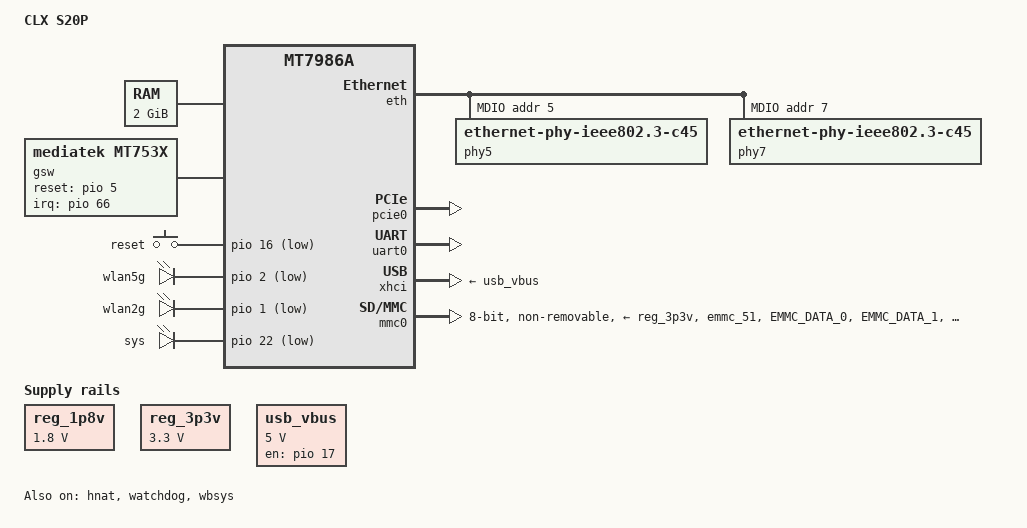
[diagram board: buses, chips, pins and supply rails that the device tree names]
// SPDX-License-Identifier: GPL-2.0-or-later OR MIT

/dts-v1/;
#include "mt7986a.dtsi"
#include "mt7986a-pinctrl.dtsi"
#include <dt-bindings/input/input.h>
#include <dt-bindings/gpio/gpio.h>
#include <dt-bindings/leds/common.h>

/ {
	model = "CLX S20P";
	compatible = "clx,s20p-gsw", "mediatek,mt7986a-emmc-rfb";

	aliases {
		led-boot = &led_sys;
		led-failsafe = &led_sys;
		led-running = &led_sys;
		led-upgrade = &led_sys;
	};

	chosen {
		bootargs = "console=ttyS0,115200n1 loglevel=8 \
			    earlycon=uart8250,mmio32,0x11002000 \
			    root=PARTLABEL=rootfs rootwait rootfstype=squashfs,f2fs";
	};

	memory {
		reg = <0 0x40000000 0 0x80000000>;
	};

	gsw: gsw@0 {
		compatible = "mediatek,mt753x";
		mediatek,ethsys = <&ethsys>;
		#address-cells = <1>;
		#size-cells = <0>;
	};

	gpio-keys {
		compatible = "gpio-keys";

		button-reset {
			label = "reset";
			linux,code = <KEY_RESTART>;
			gpios = <&pio 16 GPIO_ACTIVE_LOW>;
		};
	};

	gpio-leds {
		compatible = "gpio-leds";

		led_wlan5g: led_wlan5g {
			label = "wlan5g";
			gpios = <&pio 2 GPIO_ACTIVE_LOW>;
		};

		led_wlan2g: led_wlan2g {
			label = "wlan2g";
			gpios = <&pio 1 GPIO_ACTIVE_LOW>;
		};

		led_sys: led_sys {
			label = "sys";
			gpios = <&pio 22 GPIO_ACTIVE_LOW>;
		};
	};

	reg_1p8v: regulator-1p8v {
		compatible = "regulator-fixed";
		regulator-name = "fixed-1.8V";
		regulator-min-microvolt = <1800000>;
		regulator-max-microvolt = <1800000>;
		regulator-boot-on;
		regulator-always-on;
	};

	reg_3p3v: regulator-3p3v {
		compatible = "regulator-fixed";
		regulator-name = "fixed-3.3V";
		regulator-min-microvolt = <3300000>;
		regulator-max-microvolt = <3300000>;
		regulator-boot-on;
		regulator-always-on;
	};

	usb_vbus: regulator-usb-vbus {
		compatible = "regulator-fixed";
		regulator-name = "usb_vbus";
		regulator-min-microvolt = <5000000>;
		regulator-max-microvolt = <5000000>;
		gpios = <&pio 17 GPIO_ACTIVE_HIGH>;
		enable-active-high;
		regulator-boot-on;
	};
};

&eth {
	status = "okay";

	gmac0: mac@0 {
		compatible = "mediatek,eth-mac";
		reg = <0>;
		phy-mode = "2500base-x";
		ext-phy-reg = <5>;
		ext-phy-reset-gpios = <&pio 48 GPIO_ACTIVE_HIGH>;
		fixed-link {
			speed = <2500>;
			full-duplex;
			pause;
		};
	};

	gmac1: mac@1 {
		compatible = "mediatek,eth-mac";
		reg = <1>;
		phy-mode = "2500base-x";
		ext-phy-reg = <7>;
		ext-phy-reset-gpios = <&pio 6 GPIO_ACTIVE_HIGH>;
		fixed-link {
			speed = <2500>;
			full-duplex;
			pause;
		};
	};

	mdio: mdio-bus {
		#address-cells = <1>;
		#size-cells = <0>;

		phy5: phy@5 {
			compatible = "ethernet-phy-ieee802.3-c45";
			reg = <5>;
		};

		phy7: phy@7 {
			compatible = "ethernet-phy-ieee802.3-c45";
			reg = <7>;
		};
	};

};

&gsw {
	mediatek,mdio = <&mdio>;
	mediatek,portmap = "lllll";
	mediatek,mdio_master_pinmux = <1>;
	reset-gpios = <&pio 5 GPIO_ACTIVE_HIGH>;
	interrupt-parent = <&pio>;
	interrupts = <66 IRQ_TYPE_LEVEL_HIGH>;
	status = "okay";

	port5: port@5 {
		compatible = "mediatek,mt753x-port";
		reg = <5>;
		phy-mode = "sgmii";

		fixed-link {
			speed = <2500>;
			full-duplex;
		};
	};

	port6: port@6 {
		compatible = "mediatek,mt753x-port";
		/* mediatek,ssc-on; */
		reg = <6>;
		phy-mode = "sgmii";

		fixed-link {
			speed = <2500>;
			full-duplex;
		};
	};
};

&hnat {
	mtketh-wan = "eth1";
	mtketh-lan = "eth0";
	mtketh-max-gmac = <2>;
	ext-devices-prefix = "usb", "wwan";
	ext-devices = "wwan0_0","wwan0_1","wwan0.1","wwan0.2";
	status = "okay";
};

&pcie0 {
	pinctrl-names = "default";
	pinctrl-0 = <&pcie0_pins>;
	status = "okay";
};

&uart0 {
	status = "okay";
};

&watchdog {
	status = "okay";
};

&wbsys {
	pinctrl-names = "default", "dbdc";
	pinctrl-0 = <&wf_2g_5g_pins>;
	pinctrl-1 = <&wf_dbdc_pins>;
	status = "okay";
};

&xhci {
	vusb33-supply = <&reg_3p3v>;
	vbus-supply = <&usb_vbus>;
	status = "okay";
};

&mmc0 {
	pinctrl-names = "default", "state_uhs";
	pinctrl-0 = <&mmc0_pins_default>;
	pinctrl-1 = <&mmc0_pins_uhs>;
	bus-width = <8>;
	max-frequency = <200000000>;
	cap-mmc-highspeed;
	mmc-hs200-1_8v;
	mmc-hs400-1_8v;
	hs400-ds-delay = <0x14014>;
	vmmc-supply = <&reg_3p3v>;
	vqmmc-supply = <&reg_1p8v>;
	non-removable;
	no-sd;
	no-sdio;
	status = "okay";
};

&pio {
	mmc0_pins_default: mmc0-pins-default {
		mux {
			function = "flash";
			groups = "emmc_51";
		};
		conf-cmd-dat {
			pins = "EMMC_DATA_0", "EMMC_DATA_1", "EMMC_DATA_2",
			       "EMMC_DATA_3", "EMMC_DATA_4", "EMMC_DATA_5",
			       "EMMC_DATA_6", "EMMC_DATA_7", "EMMC_CMD";
			input-enable;
			drive-strength = <MTK_DRIVE_4mA>;
			mediatek,pull-up-adv = <1>;
		};
		conf-clk {
			pins = "EMMC_CK";
			drive-strength = <MTK_DRIVE_6mA>;
			mediatek,pull-down-adv = <2>;
		};
		conf-ds {
			pins = "EMMC_DSL";
			mediatek,pull-down-adv = <2>;
		};
		conf-rst {
			pins = "EMMC_RSTB";
			drive-strength = <MTK_DRIVE_4mA>;
			mediatek,pull-up-adv = <1>;
		};
	};

	mmc0_pins_uhs: mmc0-uhs-pins {
		mux {
			function = "flash";
			groups = "emmc_51";
		};
		conf-cmd-dat {
			pins = "EMMC_DATA_0", "EMMC_DATA_1", "EMMC_DATA_2",
			       "EMMC_DATA_3", "EMMC_DATA_4", "EMMC_DATA_5",
			       "EMMC_DATA_6", "EMMC_DATA_7", "EMMC_CMD";
			input-enable;
			drive-strength = <MTK_DRIVE_4mA>;
			mediatek,pull-up-adv = <1>;
		};
		conf-clk {
			pins = "EMMC_CK";
			drive-strength = <MTK_DRIVE_6mA>;
			mediatek,pull-down-adv = <2>;
		};
		conf-ds {
			pins = "EMMC_DSL";
			mediatek,pull-down-adv = <2>;
		};
		conf-rst {
			pins = "EMMC_RSTB";
			drive-strength = <MTK_DRIVE_4mA>;
			mediatek,pull-up-adv = <1>;
		};
	};

	wf_2g_5g_pins: wf_2g_5g-pins {
		mux {
			function = "wifi";
			groups = "wf_2g", "wf_5g";
		};
		conf {
			pins = "WF0_HB1", "WF0_HB2", "WF0_HB3", "WF0_HB4",
			       "WF0_HB0", "WF0_HB0_B", "WF0_HB5", "WF0_HB6",
			       "WF0_HB7", "WF0_HB8", "WF0_HB9", "WF0_HB10",
			       "WF0_TOP_CLK", "WF0_TOP_DATA", "WF1_HB1",
			       "WF1_HB2", "WF1_HB3", "WF1_HB4", "WF1_HB0",
			       "WF1_HB5", "WF1_HB6", "WF1_HB7", "WF1_HB8",
			       "WF1_TOP_CLK", "WF1_TOP_DATA";
			drive-strength = <MTK_DRIVE_4mA>;
		};
	};

	wf_dbdc_pins: wf_dbdc-pins {
		mux {
			function = "wifi";
			groups = "wf_dbdc";
		};
		conf {
			pins = "WF0_HB1", "WF0_HB2", "WF0_HB3", "WF0_HB4",
			       "WF0_HB0", "WF0_HB0_B", "WF0_HB5", "WF0_HB6",
			       "WF0_HB7", "WF0_HB8", "WF0_HB9", "WF0_HB10",
			       "WF0_TOP_CLK", "WF0_TOP_DATA", "WF1_HB1",
			       "WF1_HB2", "WF1_HB3", "WF1_HB4", "WF1_HB0",
			       "WF1_HB5", "WF1_HB6", "WF1_HB7", "WF1_HB8",
			       "WF1_TOP_CLK", "WF1_TOP_DATA";
			drive-strength = <MTK_DRIVE_4mA>;
		};
	};
};
